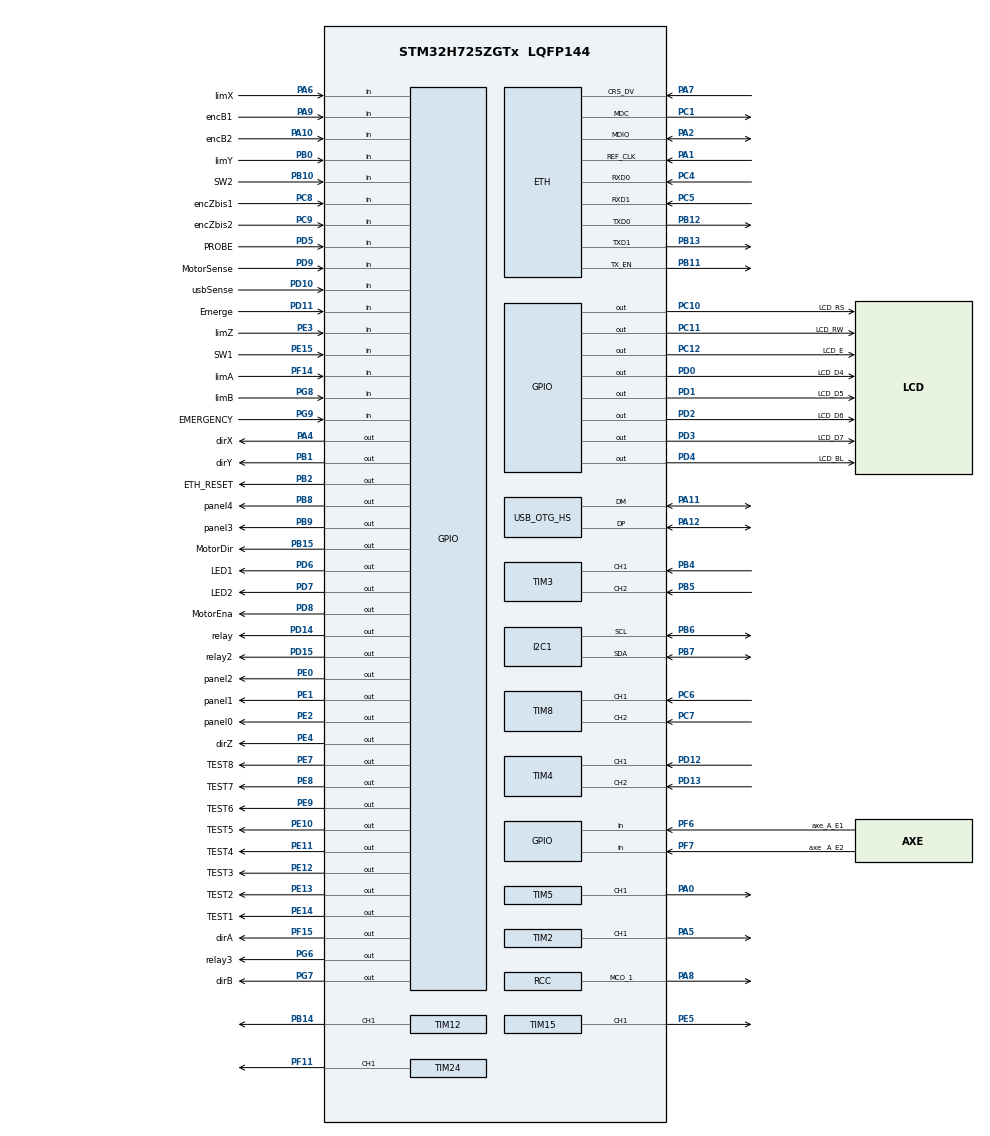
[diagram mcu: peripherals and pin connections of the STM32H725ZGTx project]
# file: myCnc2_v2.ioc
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ETH.MediaInterface=HAL_ETH_RMII_MODE
IWDG1.Prescaler=IWDG_PRESCALER_64
Mcu.Family=STM32H7
Mcu.Name=STM32H725ZGTx
Mcu.Package=LQFP144
Mcu.UserConstants=SPINDLE_TIMER,htim12;AXE_Z_TIMER,htim15;SPEED_TIMER,htim16;AXE_A_TIMER,htim24;SYNC_TIMER,htim23;AXE_Y_TIMER,htim5;ENC_Z_TIMER,htim8;AXE_X_TIMER,htim2;ENC_X_TIMER,htim3;MASTER_TIMER,htim1;ENC_Y_TIMER,htim4;AXE_B_TIMER,htim8;SPEED_PERIOD,10;configRUNTIME_TIMER,htim7;MASTER_FREQ,150000000;HIWDG_,hiwdg1
NVIC.ETH_IRQn=true\:14\:0\:true\:false\:true\:true\:true\:true
NVIC.PriorityGroup=NVIC_PRIORITYGROUP_4
NVIC.TIM15_IRQn=true\:9\:0\:true\:false\:true\:true\:true\:true
NVIC.TIM16_IRQn=true\:12\:0\:true\:false\:true\:true\:true\:true
NVIC.TIM23_IRQn=true\:8\:0\:true\:false\:true\:true\:true\:true
NVIC.TIM24_IRQn=true\:9\:0\:true\:false\:true\:true\:true\:true
NVIC.TIM2_IRQn=true\:9\:0\:true\:false\:true\:true\:true\:true
NVIC.TIM5_IRQn=true\:9\:0\:true\:false\:true\:true\:true\:true
NVIC.TIM6_DAC_IRQn=true\:15\:0\:false\:false\:true\:false\:true\:true
NVIC.TimeBase=TIM6_DAC_IRQn
NVIC.TimeBaseIP=TIM6
PA0.GPIO_PuPd=GPIO_NOPULL
PA0.GPIO_Speed=GPIO_SPEED_FREQ_HIGH
PA0.Signal=S_TIM5_CH1
PA1.GPIO_Speed=GPIO_SPEED_FREQ_VERY_HIGH
PA1.Mode=RMII
PA1.Signal=ETH_REF_CLK
PA10.GPIO_Label=encB2
PA10.Signal=GPIO_Input
PA11.Mode=Device_Only_FS
PA11.Signal=USB_OTG_HS_DM
PA12.Mode=Device_Only_FS
PA12.Signal=USB_OTG_HS_DP
PA13(JTMS/SWDIO).Mode=JTAG_4_pins
PA13(JTMS/SWDIO).Signal=DEBUG_JTMS-SWDIO
PA14(JTCK/SWCLK).Mode=JTAG_4_pins
PA14(JTCK/SWCLK).Signal=DEBUG_JTCK-SWCLK
PA15(JTDI).Mode=JTAG_4_pins
PA15(JTDI).Signal=DEBUG_JTDI
PA2.GPIO_Speed=GPIO_SPEED_FREQ_VERY_HIGH
PA2.Mode=RMII
PA2.Signal=ETH_MDIO
PA4.GPIO_Label=dirX
PA4.GPIO_Speed=GPIO_SPEED_FREQ_HIGH
PA4.Signal=GPIO_Output
PA5.GPIO_PuPd=GPIO_NOPULL
PA5.GPIO_Speed=GPIO_SPEED_FREQ_HIGH
PA5.Signal=S_TIM2_CH1_ETR
PA6.GPIO_Label=limX
PA6.GPIO_PuPd=GPIO_PULLUP
PA6.Signal=GPIO_Input
PA7.GPIO_Speed=GPIO_SPEED_FREQ_VERY_HIGH
PA7.Mode=RMII
PA7.Signal=ETH_CRS_DV
PA8.GPIO_Speed=GPIO_SPEED_FREQ_VERY_HIGH
PA8.Mode=Clock-out-1
PA8.Signal=RCC_MCO_1
PA9.GPIO_Label=encB1
PA9.Signal=GPIO_Input
PB0.GPIO_Label=limY
PB0.GPIO_PuPd=GPIO_PULLUP
PB0.Signal=GPIO_Input
PB1.GPIO_Label=dirY
PB1.GPIO_Speed=GPIO_SPEED_FREQ_HIGH
PB1.Signal=GPIO_Output
PB10.GPIO_Label=SW2
PB10.GPIO_PuPd=GPIO_PULLUP
PB10.Signal=GPIO_Input
PB11.GPIO_Speed=GPIO_SPEED_FREQ_VERY_HIGH
PB11.Mode=RMII
PB11.Signal=ETH_TX_EN
PB12.GPIO_Speed=GPIO_SPEED_FREQ_VERY_HIGH
PB12.Mode=RMII
PB12.Signal=ETH_TXD0
PB13.GPIO_Speed=GPIO_SPEED_FREQ_VERY_HIGH
PB13.Mode=RMII
PB13.Signal=ETH_TXD1
PB14.GPIO_Speed=GPIO_SPEED_FREQ_HIGH
PB14.Signal=S_TIM12_CH1
PB15.GPIO_Label=MotorDir
PB15.Signal=GPIO_Output
PB2.GPIO_Label=ETH_RESET
PB2.Signal=GPIO_Output
PB3(JTDO/TRACESWO).Mode=JTAG_4_pins
PB3(JTDO/TRACESWO).Signal=DEBUG_JTDO-SWO
PB4(NJTRST).GPIO_PuPd=GPIO_NOPULL
PB4(NJTRST).GPIO_Speed=GPIO_SPEED_FREQ_HIGH
PB4(NJTRST).Signal=S_TIM3_CH1
PB5.GPIO_PuPd=GPIO_NOPULL
PB5.GPIO_Speed=GPIO_SPEED_FREQ_HIGH
PB5.Signal=S_TIM3_CH2
PB6.Mode=I2C
PB6.Signal=I2C1_SCL
PB7.Mode=I2C
PB7.Signal=I2C1_SDA
PB8.GPIO_Label=panel4
PB8.Signal=GPIO_Output
PB9.GPIO_Label=panel3
PB9.Signal=GPIO_Output
PC1.GPIO_Speed=GPIO_SPEED_FREQ_VERY_HIGH
PC1.Mode=RMII
PC1.Signal=ETH_MDC
PC10.GPIO_Label=LCD_RS
PC10.Signal=GPIO_Output
PC11.GPIO_Label=LCD_RW
PC11.Signal=GPIO_Output
PC12.GPIO_Label=LCD_E
PC12.Signal=GPIO_Output
PC14-OSC32_IN.Mode=LSE-External-Oscillator
PC14-OSC32_IN.Signal=RCC_OSC32_IN
PC15-OSC32_OUT.Mode=LSE-External-Oscillator
PC15-OSC32_OUT.Signal=RCC_OSC32_OUT
PC4.GPIO_Speed=GPIO_SPEED_FREQ_VERY_HIGH
PC4.Mode=RMII
PC4.Signal=ETH_RXD0
PC5.GPIO_Speed=GPIO_SPEED_FREQ_VERY_HIGH
PC5.Mode=RMII
PC5.Signal=ETH_RXD1
PC6.GPIO_Speed=GPIO_SPEED_FREQ_HIGH
PC6.Signal=S_TIM8_CH1
PC7.GPIO_Speed=GPIO_SPEED_FREQ_HIGH
PC7.Signal=S_TIM8_CH2
PC8.GPIO_Label=encZbis1
PC8.Signal=GPIO_Input
PC9.GPIO_Label=encZbis2
PC9.Signal=GPIO_Input
PD0.GPIO_Label=LCD_D4
PD0.Signal=GPIO_Output
PD1.GPIO_Label=LCD_D5
PD1.Signal=GPIO_Output
PD10.GPIO_Label=usbSense
PD10.Signal=GPIO_Input
PD11.GPIO_Label=Emerge
PD11.GPIO_PuPd=GPIO_PULLUP
PD11.Signal=GPIO_Input
PD12.GPIO_Speed=GPIO_SPEED_FREQ_HIGH
PD12.Signal=S_TIM4_CH1
PD13.GPIO_Speed=GPIO_SPEED_FREQ_HIGH
PD13.Signal=S_TIM4_CH2
PD14.GPIO_Label=relay
PD14.Signal=GPIO_Output
PD15.GPIO_Label=relay2
PD15.Signal=GPIO_Output
PD2.GPIO_Label=LCD_D6
PD2.Signal=GPIO_Output
PD3.GPIO_Label=LCD_D7
PD3.Signal=GPIO_Output
PD4.GPIO_Label=LCD_BL
PD4.Signal=GPIO_Output
PD5.GPIO_Label=PROBE
PD5.GPIO_PuPd=GPIO_PULLUP
PD5.Signal=GPIO_Input
PD6.GPIO_Label=LED1
PD6.Signal=GPIO_Output
PD7.GPIO_Label=LED2
PD7.Signal=GPIO_Output
PD8.GPIO_Label=MotorEna
PD8.Signal=GPIO_Output
PD9.GPIO_Label=MotorSense
PD9.Signal=GPIO_Input
PE0.GPIO_Label=panel2
PE0.Signal=GPIO_Output
PE1.GPIO_Label=panel1
PE1.Signal=GPIO_Output
PE10.GPIO_Label=TEST5
PE10.Signal=GPIO_Output
PE11.GPIO_Label=TEST4
PE11.Signal=GPIO_Output
PE12.GPIO_Label=TEST3
PE12.Signal=GPIO_Output
PE13.GPIO_Label=TEST2
PE13.Signal=GPIO_Output
PE14.GPIO_Label=TEST1
PE14.Signal=GPIO_Output
PE15.GPIO_Label=SW1
PE15.GPIO_PuPd=GPIO_PULLUP
PE15.Signal=GPIO_Input
PE2.GPIO_Label=panel0
PE2.Signal=GPIO_Output
PE3.GPIO_Label=limZ
PE3.GPIO_PuPd=GPIO_PULLUP
PE3.Signal=GPIO_Input
PE4.GPIO_Label=dirZ
PE4.GPIO_Speed=GPIO_SPEED_FREQ_HIGH
PE4.Signal=GPIO_Output
PE5.GPIO_Speed=GPIO_SPEED_FREQ_HIGH
PE5.Signal=S_TIM15_CH1
PE7.GPIO_Label=TEST8
PE7.Signal=GPIO_Output
PE8.GPIO_Label=TEST7
PE8.Signal=GPIO_Output
PE9.GPIO_Label=TEST6
PE9.Signal=GPIO_Output
PF11.Mode=PWM Generation1 CH1
PF11.Signal=TIM24_CH1
PF14.GPIO_Label=limA
PF14.GPIO_PuPd=GPIO_PULLUP
PF14.Signal=GPIO_Input
PF15.GPIO_Label=dirA
PF15.GPIO_Speed=GPIO_SPEED_FREQ_HIGH
PF15.Signal=GPIO_Output
PF6.GPIO_Label=axe_A_E1
PF6.GPIO_PuPd=GPIO_PULLUP
PF6.Signal=GPIO_Input
PF7.GPIO_Label=axe _A_E2
PF7.GPIO_PuPd=GPIO_PULLUP
PF7.Signal=GPIO_Input
PG6.GPIO_Label=relay3
PG6.Signal=GPIO_Output
PG7.GPIO_Label=dirB
PG7.GPIO_Speed=GPIO_SPEED_FREQ_HIGH
PG7.Signal=GPIO_Output
PG8.GPIO_Label=limB
PG8.GPIO_PuPd=GPIO_PULLUP
PG8.Signal=GPIO_Input
PG9.GPIO_Label=EMERGENCY
PG9.Signal=GPIO_Input
PH0-OSC_IN.Mode=HSE-External-Oscillator
PH0-OSC_IN.Signal=RCC_OSC_IN
PH1-OSC_OUT.Mode=HSE-External-Oscillator
PH1-OSC_OUT.Signal=RCC_OSC_OUT
ProjectManager.HeapSize=0x200
ProjectManager.StackSize=0x400
ProjectManager.TargetToolchain=Makefile
RCC.ADCFreq_Value=125000000
RCC.APB1Freq_Value=75000000
RCC.APB2Freq_Value=75000000
RCC.APB3Freq_Value=75000000
RCC.APB4Freq_Value=75000000
RCC.CortexFreq_Value=37500000
RCC.Cortex_Div=SYSTICK_CLKSOURCE_HCLK_DIV8
RCC.D1PPRE=RCC_APB3_DIV2
RCC.D2PPRE1=RCC_APB1_DIV2
RCC.D2PPRE2=RCC_APB2_DIV2
RCC.D3PPRE=RCC_APB4_DIV2
RCC.DIVM1=5
RCC.DIVM2=5
RCC.DIVM3=5
RCC.DIVN1=60
RCC.DIVN2=50
RCC.DIVN3=48
RCC.DIVP1=1
RCC.DIVQ1=6
RCC.DIVQ3=5
RCC.HCLKFreq_Value=150000000
RCC.HPRE=RCC_HCLK_DIV2
RCC.I2C123CLockSelection=RCC_I2C1235CLKSOURCE_HSI
RCC.RCC_MCO1Source=RCC_MCO1SOURCE_PLL1QCLK
RCC.RTCClockSelection=RCC_RTCCLKSOURCE_LSE
RCC.SYSCLKFreq_VALUE=300000000
RCC.SYSCLKSource=RCC_SYSCLKSOURCE_PLLCLK
RCC.SupplySource=PWR_LDO_SUPPLY
RCC.USBCLockSelection=RCC_USBCLKSOURCE_PLL3
RCC.USBFreq_Value=48000000
SH.S_TIM12_CH1.0=TIM12_CH1,PWM Generation1 CH1
SH.S_TIM15_CH1.0=TIM15_CH1,PWM Generation1 CH1
SH.S_TIM2_CH1_ETR.0=TIM2_CH1,PWM Generation1 CH1
SH.S_TIM3_CH1.0=TIM3_CH1,Encoder_Interface
SH.S_TIM3_CH2.0=TIM3_CH2,Encoder_Interface
SH.S_TIM4_CH1.0=TIM4_CH1,Encoder_Interface
SH.S_TIM4_CH2.0=TIM4_CH2,Encoder_Interface
SH.S_TIM5_CH1.0=TIM5_CH1,PWM Generation1 CH1
SH.S_TIM8_CH1.0=TIM8_CH1,Encoder_Interface
SH.S_TIM8_CH2.0=TIM8_CH2,Encoder_Interface
TIM1.Period=100
TIM1.TIM_MasterOutputTrigger=TIM_TRGO_UPDATE
TIM1.TIM_MasterSlaveMode=TIM_MASTERSLAVEMODE_ENABLE
TIM12.AutoReloadPreload=TIM_AUTORELOAD_PRELOAD_ENABLE
TIM12.Channel-PWM\ Generation1\ CH1=TIM_CHANNEL_1
TIM12.OCPolarity_1=TIM_OCPOLARITY_LOW
TIM12.Period=9999
TIM12.Prescaler=99
TIM15.AutoReloadPreload=TIM_AUTORELOAD_PRELOAD_ENABLE
TIM15.Channel-Output\ Compare2\ No\ Output=TIM_CHANNEL_2
TIM15.Channel-PWM\ Generation1\ CH1=TIM_CHANNEL_1
TIM15.Pulse-Output\ Compare2\ No\ Output=10
TIM15.Pulse-PWM\ Generation1\ CH1=10
TIM16.Period=((100 * SPEED_PERIOD)-1)
TIM16.Prescaler=1499
TIM2.AutoReloadPreload=TIM_AUTORELOAD_PRELOAD_ENABLE
TIM2.Channel-Output\ Compare2\ No\ Output=TIM_CHANNEL_2
TIM2.Channel-PWM\ Generation1\ CH1=TIM_CHANNEL_1
TIM2.Pulse-Output\ Compare2\ No\ Output=10
TIM2.Pulse-PWM\ Generation1\ CH1=10
TIM24.AutoReloadPreload=TIM_AUTORELOAD_PRELOAD_ENABLE
TIM24.Channel-Output\ Compare2\ No\ Output=TIM_CHANNEL_2
TIM24.Channel-PWM\ Generation1\ CH1=TIM_CHANNEL_1
TIM24.Pulse-Output\ Compare2\ No\ Output=10
TIM24.Pulse-PWM\ Generation1\ CH1=10
TIM5.AutoReloadPreload=TIM_AUTORELOAD_PRELOAD_ENABLE
TIM5.Channel-Output\ Compare2\ No\ Output=TIM_CHANNEL_2
TIM5.Channel-PWM\ Generation1\ CH1=TIM_CHANNEL_1
TIM5.Pulse-Output\ Compare2\ No\ Output=10
TIM5.Pulse-PWM\ Generation1\ CH1=10
TIM7.Prescaler=1000
USB_OTG_HS.VirtualMode-Device_Only_FS=Device_Only_FS
VP_IWDG1_VS_IWDG.Mode=IWDG_Activate
VP_MEMORYMAP_VS_MEMORYMAP.Mode=CurAppReg
VP_RNG_VS_RNG.Mode=RNG_Activate
VP_RTC_VS_RTC_Activate.Mode=RTC_Enabled
VP_SYS_VS_tim6.Mode=TIM6
VP_TIM12_VS_ClockSourceINT.Mode=Internal
VP_TIM15_VS_ClockSourceITR.Mode=TriggerSource_ITR0
VP_TIM15_VS_ControllerModeClock.Mode=Clock Mode
VP_TIM15_VS_no_output2.Mode=Output Compare2 No Output
VP_TIM16_VS_ClockSourceINT.Mode=Enable_Timer
VP_TIM1_VS_ClockSourceINT.Mode=Internal
VP_TIM23_VS_ClockSourceITR.Mode=TriggerSource_ITR0
VP_TIM23_VS_ControllerModeClock.Mode=Clock Mode
VP_TIM24_VS_ClockSourceITR.Mode=TriggerSource_ITR0
VP_TIM24_VS_ControllerModeClock.Mode=Clock Mode
VP_TIM24_VS_no_output2.Mode=Output Compare2 No Output
VP_TIM2_VS_ClockSourceITR.Mode=TriggerSource_ITR0
VP_TIM2_VS_ControllerModeClock.Mode=Clock Mode
VP_TIM2_VS_no_output2.Mode=Output Compare2 No Output
VP_TIM5_VS_ClockSourceITR.Mode=TriggerSource_ITR0
VP_TIM5_VS_ControllerModeClock.Mode=Clock Mode
VP_TIM5_VS_no_output2.Mode=Output Compare2 No Output
VP_TIM7_VS_ClockSourceINT.Mode=Enable_Timer
board=custom

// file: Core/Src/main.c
/* USER CODE BEGIN Header */
/**
  ******************************************************************************
  * @file           : main.c
  * @brief          : Main program body
  ******************************************************************************
  * @attention
  *
  * Copyright (c) 2025 STMicroelectronics.
  * All rights reserved.
  *
  * This software is licensed under terms that can be found in the LICENSE file
  * in the root directory of this software component.
  * If no LICENSE file comes with this software, it is provided AS-IS.
  *
  ******************************************************************************
  */
/* USER CODE END Header */
#include "main.h"
#include "eth.h"
#include "i2c.h"
#include "iwdg.h"
#include "memorymap.h"
#include "rng.h"
#include "rtc.h"
#include "tim.h"
#include "usb_otg.h"
#include "gpio.h"

/* USER CODE BEGIN Includes */
#include "CNC2_Main.hpp"
/* USER CODE END Includes */

void SystemClock_Config(void);

int main(void)
{

  /* MCU Configuration--------------------------------------------------------*/

  /* Reset of all peripherals, Initializes the Flash interface and the Systick. */
  HAL_Init();

  /* Configure the system clock */
  SystemClock_Config();

  /* Initialize all configured peripherals */
  MX_GPIO_Init();
  MX_ETH_Init();
  MX_TIM1_Init();
  MX_TIM2_Init();
  MX_TIM3_Init();
  MX_TIM4_Init();
  MX_TIM5_Init();
  MX_TIM8_Init();
  MX_TIM12_Init();
  MX_TIM15_Init();
  MX_TIM23_Init();
  MX_TIM24_Init();
  MX_USB_OTG_HS_PCD_Init();
  MX_I2C1_Init();
  MX_RTC_Init();
  MX_TIM7_Init();
  MX_TIM16_Init();
  MX_RNG_Init();
  MX_IWDG1_Init();
  /* USER CODE BEGIN 2 */

  ApplMain();
  /* USER CODE END 2 */

  /* Infinite loop */
  while (1)
  {

  }
}

void SystemClock_Config(void)
{
  RCC_OscInitTypeDef RCC_OscInitStruct = {0};
  RCC_ClkInitTypeDef RCC_ClkInitStruct = {0};

  /** Supply configuration update enable
  */
  HAL_PWREx_ConfigSupply(PWR_LDO_SUPPLY);

  /** Configure the main internal regulator output voltage
  */
  __HAL_PWR_VOLTAGESCALING_CONFIG(PWR_REGULATOR_VOLTAGE_SCALE2);

  while(!__HAL_PWR_GET_FLAG(PWR_FLAG_VOSRDY)) {}

  /** Configure LSE Drive Capability
  */
  HAL_PWR_EnableBkUpAccess();
  __HAL_RCC_LSEDRIVE_CONFIG(RCC_LSEDRIVE_LOW);

  /** Initializes the RCC Oscillators according to the specified parameters
  * in the RCC_OscInitTypeDef structure.
  */
  RCC_OscInitStruct.OscillatorType = RCC_OSCILLATORTYPE_HSI48|RCC_OSCILLATORTYPE_HSI
                              |RCC_OSCILLATORTYPE_LSI|RCC_OSCILLATORTYPE_HSE
                              |RCC_OSCILLATORTYPE_LSE;
  RCC_OscInitStruct.HSEState = RCC_HSE_ON;
  RCC_OscInitStruct.LSEState = RCC_LSE_ON;
  RCC_OscInitStruct.HSIState = RCC_HSI_DIV1;
  RCC_OscInitStruct.HSICalibrationValue = 64;
  RCC_OscInitStruct.LSIState = RCC_LSI_ON;
  RCC_OscInitStruct.HSI48State = RCC_HSI48_ON;
  RCC_OscInitStruct.PLL.PLLState = RCC_PLL_ON;
  RCC_OscInitStruct.PLL.PLLSource = RCC_PLLSOURCE_HSE;
  RCC_OscInitStruct.PLL.PLLM = 5;
  RCC_OscInitStruct.PLL.PLLN = 60;
  RCC_OscInitStruct.PLL.PLLP = 1;
  RCC_OscInitStruct.PLL.PLLQ = 6;
  RCC_OscInitStruct.PLL.PLLR = 2;
  RCC_OscInitStruct.PLL.PLLRGE = RCC_PLL1VCIRANGE_2;
  RCC_OscInitStruct.PLL.PLLVCOSEL = RCC_PLL1VCOWIDE;
  RCC_OscInitStruct.PLL.PLLFRACN = 0;
  if (HAL_RCC_OscConfig(&RCC_OscInitStruct) != HAL_OK)
  {
    Error_Handler();
  }

  /** Initializes the CPU, AHB and APB buses clocks
  */
  RCC_ClkInitStruct.ClockType = RCC_CLOCKTYPE_HCLK|RCC_CLOCKTYPE_SYSCLK
                              |RCC_CLOCKTYPE_PCLK1|RCC_CLOCKTYPE_PCLK2
                              |RCC_CLOCKTYPE_D3PCLK1|RCC_CLOCKTYPE_D1PCLK1;
  RCC_ClkInitStruct.SYSCLKSource = RCC_SYSCLKSOURCE_PLLCLK;
  RCC_ClkInitStruct.SYSCLKDivider = RCC_SYSCLK_DIV1;
  RCC_ClkInitStruct.AHBCLKDivider = RCC_HCLK_DIV2;
  RCC_ClkInitStruct.APB3CLKDivider = RCC_APB3_DIV2;
  RCC_ClkInitStruct.APB1CLKDivider = RCC_APB1_DIV2;
  RCC_ClkInitStruct.APB2CLKDivider = RCC_APB2_DIV2;
  RCC_ClkInitStruct.APB4CLKDivider = RCC_APB4_DIV2;

  if (HAL_RCC_ClockConfig(&RCC_ClkInitStruct, FLASH_LATENCY_2) != HAL_OK)
  {
    Error_Handler();
  }
  __HAL_RCC_PLLCLKOUT_ENABLE(RCC_PLL1_DIVQ);
  HAL_RCC_MCOConfig(RCC_MCO1, RCC_MCO1SOURCE_PLL1QCLK, RCC_MCODIV_1);
}

void HAL_TIM_PeriodElapsedCallback(TIM_HandleTypeDef *htim)
{
  if (htim->Instance == TIM6)
  {
    HAL_IncTick();
  }
}

void Error_Handler(void)
{
  __disable_irq();
  while (1)
  {
  }
}
